VERSION ""

NS_ :

BS_:

BU_: DASH

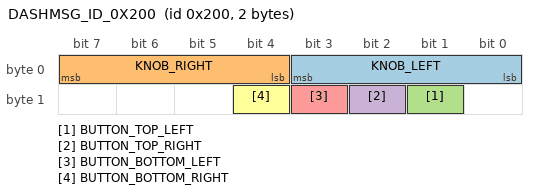
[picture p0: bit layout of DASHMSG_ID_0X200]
BO_ 512 DASHMSG_ID_0X200: 2 DASH
 SG_ KNOB_LEFT : 0|4@1+ (1,0) [0|10] "" Vector__XXX
 SG_ KNOB_RIGHT : 4|4@1+ (1,0) [0|10] "" Vector__XXX
 SG_ BUTTON_TOP_LEFT : 9|1@0+ (1,0) [0|1] "bool" Vector__XXX
 SG_ BUTTON_TOP_RIGHT : 10|1@0+ (1,0) [0|1] "bool" Vector__XXX
 SG_ BUTTON_BOTTOM_LEFT : 11|1@0+ (1,0) [0|1] "bool" Vector__XXX
 SG_ BUTTON_BOTTOM_RIGHT : 12|1@0+ (1,0) [0|1] "bool" Vector__XXX

BA_DEF_  "BusType" STRING ;
BA_DEF_DEF_  "BusType" "CAN";
